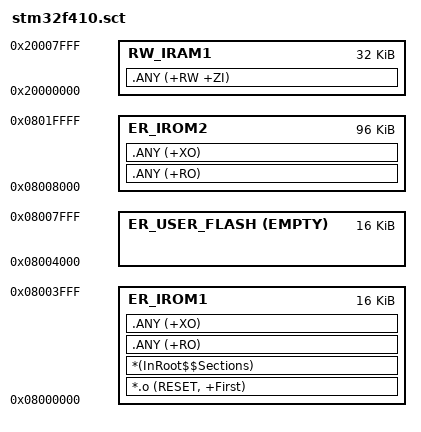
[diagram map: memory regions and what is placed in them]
; *************************************************************
; *** STM32F410RBT Scatter-Loading Description File       ***
; *************************************************************

; 1. Flash: Başlangıç
LR_IROM1 0x08000000 0x00004000  {    
  ER_IROM1 0x08000000 0x00004000  {    
    *.o (RESET, +First)
    *(InRoot$$Sections)
    .ANY (+RO)
    .ANY (+XO)
  }
}

; 2. Flash: User Bölgesi
LR_IROM_USER 0x08004000 0x00004000 {
  ER_USER_FLASH 0x08004000 EMPTY 0x00004000 {
  }
}

; 3. Flash: Uygulama Kodu
LR_IROM2 0x08008000 0x00018000  {
  ER_IROM2 0x08008000 0x00018000  {    
    .ANY (+RO)
    .ANY (+XO)
  }
}

; 4. RAM: Veriler (Flash'ın DIŞINDA ayrı bir Load Region olarak tanımlandı)
LR_IRAM1 0x20000000 0x00008000  {    
  RW_IRAM1 0x20000000 0x00008000  {    
    .ANY (+RW +ZI)
  }
}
